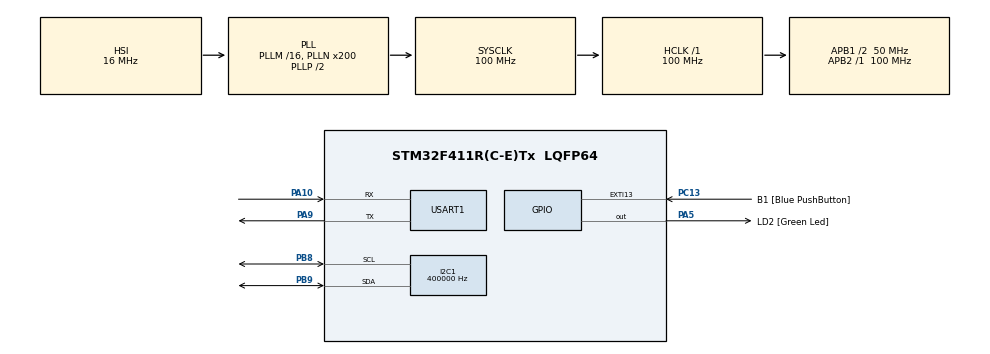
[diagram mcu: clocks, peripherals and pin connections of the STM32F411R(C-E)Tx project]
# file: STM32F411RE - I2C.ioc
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I2C1.ClockSpeed=400000
Mcu.Family=STM32F4
Mcu.Name=STM32F411R(C-E)Tx
Mcu.Package=LQFP64
NVIC.PriorityGroup=NVIC_PRIORITYGROUP_0
NVIC.RTC_Alarm_IRQn=true\:0\:0
NVIC.RTC_WKUP_IRQn=true\:0\:0
PA10.Mode=Asynchronous
PA10.Signal=USART1_RX
PA13.GPIO_Label=TMS
PA13.Mode=Trace-Asynchronous_SW
PA13.Signal=SYS_JTMS-SWDIO
PA14.GPIO_Label=TCK
PA14.Mode=Trace-Asynchronous_SW
PA14.Signal=SYS_JTCK-SWCLK
PA2.GPIO_Label=USART_TX
PA2.GPIO_Mode=GPIO_MODE_AF_PP
PA2.GPIO_PuPd=GPIO_PULLUP
PA2.GPIO_Speed=GPIO_SPEED_LOW
PA2.Signal=USART2_TX
PA3.GPIO_Label=USART_RX
PA3.GPIO_Mode=GPIO_MODE_AF_PP
PA3.GPIO_PuPd=GPIO_PULLUP
PA3.GPIO_Speed=GPIO_SPEED_LOW
PA3.Signal=USART2_RX
PA5.GPIO_Label=LD2 [Green Led]
PA5.GPIO_ModeDefaultOutputPP=GPIO_MODE_OUTPUT_PP
PA5.GPIO_PuPd=GPIO_NOPULL
PA5.GPIO_Speed=GPIO_SPEED_LOW
PA5.Signal=GPIO_Output
PA9.Mode=Asynchronous
PA9.Signal=USART1_TX
PB3.GPIO_Label=SWO
PB3.Mode=Trace-Asynchronous_SW
PB3.Signal=SYS_JTDO-SWO
PB8.GPIO_Mode=GPIO_MODE_AF_OD
PB8.GPIO_PuPd=GPIO_NOPULL
PB8.GPIO_Speed=GPIO_SPEED_MEDIUM
PB8.Mode=I2C
PB8.Signal=I2C1_SCL
PB9.GPIO_Mode=GPIO_MODE_AF_OD
PB9.GPIO_PuPd=GPIO_NOPULL
PB9.GPIO_Speed=GPIO_SPEED_MEDIUM
PB9.Mode=I2C
PB9.Signal=I2C1_SDA
PC13-ANTI_TAMP.GPIO_Label=B1 [Blue PushButton]
PC13-ANTI_TAMP.GPIO_ModeDefaultEXTI=GPIO_MODE_EVT_RISING
PC13-ANTI_TAMP.GPIO_PuPd=GPIO_NOPULL
PC13-ANTI_TAMP.Signal=GPXTI13
PC14-OSC32_IN.Mode=LSE-External-Oscillator
PC14-OSC32_IN.Signal=RCC_OSC32_IN
PC15-OSC32_OUT.Mode=LSE-External-Oscillator
PC15-OSC32_OUT.Signal=RCC_OSC32_OUT
PH0\ -\ OSC_IN.Signal=RCC_OSC_IN
PH1\ -\ OSC_OUT.Signal=RCC_OSC_OUT
ProjectManager.TargetToolchain=EWARM 6.70
RCC.48MHZClocksFreq_Value=50000000
RCC.AHBFreq_Value=100000000
RCC.APB1CLKDivider=RCC_HCLK_DIV2
RCC.APB1Freq_Value=50000000
RCC.APB1TimFreq_Value=100000000
RCC.APB2Freq_Value=100000000
RCC.APB2TimFreq_Value=100000000
RCC.ClockTypePCLK1-ClockTree=RCC_CLOCKTYPE_PCLK1
RCC.ClockTypeSysClk-ClockTree=RCC_CLOCKTYPE_SYSCLK
RCC.CortexFreq_Value=12500000
RCC.EnableExtClockForI2S-ClockTree=false
RCC.EnableHSE-ClockTree=false
RCC.EnableHSERTCDevisor-ClockTree=false
RCC.EnableLSE-ClockTree=true
RCC.EnableLSERTC-ClockTree=true
RCC.ExtClockEnable-ClockTree=false
RCC.FLatency-AdvancedSettings=FLASH_LATENCY_3
RCC.HCLKFreq_Value=100000000
RCC.HSEState-ClockTree=RCC_HSE_OFF
RCC.HSE_VALUE=8000000
RCC.HSIState-ClockTree=RCC_HSI_ON
RCC.HSI_VALUE=16000000
RCC.I2SEnable-ClockTree=false
RCC.IWDGEnable-ClockTree=false
RCC.LSEState-ClockTree=RCC_LSE_ON
RCC.LSE_VALUE=32768
RCC.LSIState-ClockTree=RCC_LSI_OFF
RCC.MCO1OutPutEnable-ClockTree=false
RCC.MCO2OutPutEnable-ClockTree=false
RCC.OscillatorTypeHSI-ClockTree=RCC_OSCILLATORTYPE_HSI
RCC.OscillatorTypeLSE-ClockTree=RCC_OSCILLATORTYPE_LSE
RCC.PLLN=200
RCC.PLLState-ClockTree=RCC_PLL_ON
RCC.PWR_Regulator_Voltage_Scale-AdvancedSettings=PWR_REGULATOR_VOLTAGE_SCALE2
RCC.RCC_PERIPHCLK_RTCVar-ClockTree=RCC_PERIPHCLK_RTC
RCC.RCC_RTC_Clock_Source=RCC_RTCCLKSOURCE_LSE
RCC.RNGEnable-ClockTree=false
RCC.RTCEnable-ClockTree=true
RCC.SDIOEnable-ClockTree=false
RCC.SYSCLKFreq_VALUE=100000000
RCC.SYSCLKSource=RCC_SYSCLKSOURCE_PLLCLK
RCC.USBFSEnable-ClockTree=false
RCC.USBHSEnable-ClockTree=false
RCC.VCOOutputFreq_Value=200000000
RTC.Alarm-Alarm\ A=RTC_ALARM_A
RTC.Alarm_B-Alarm\ B=RTC_ALARM_B
RTC.Format=FORMAT_BIN
RTC.OutPut-Alarm\ A=RTC_OUTPUT_DISABLE
RTC.OutPut-Alarm\ B=RTC_OUTPUT_DISABLE
RTC.OutPut-WakeUp=RTC_OUTPUT_DISABLE
RTC.WakeUpClock-WakeUp=RTC_WAKEUPCLOCK_RTCCLK_DIV2
RTC.WakeUpCounter-WakeUp=196
USART1.HwFlowCtl-Asynchronous=UART_HWCONTROL_NONE
USART1.VirtualMode-Asynchronous=VM_ASYNC
VP_RTC_VS_RTC_Alarm_A_Intern.Mode=Alarm A
VP_RTC_VS_RTC_Alarm_B_Intern.Mode=Alarm B
VP_RTC_VS_RTC_WakeUp_intern.Mode=WakeUp

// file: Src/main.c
/**
  ******************************************************************************
  * File Name          : main.c
  * Date               : 27/04/2015 14:41:06
  * Description        : Main program body
  ******************************************************************************
  *
  * COPYRIGHT(c) 2015 STMicroelectronics
  *
  * Redistribution and use in source and binary forms, with or without modification,
  * are permitted provided that the following conditions are met:
  *   1. Redistributions of source code must retain the above copyright notice,
  *      this list of conditions and the following disclaimer.
  *   2. Redistributions in binary form must reproduce the above copyright notice,
  *      this list of conditions and the following disclaimer in the documentation
  *      and/or other materials provided with the distribution.
  *   3. Neither the name of STMicroelectronics nor the names of its contributors
  *      may be used to endorse or promote products derived from this software
  *      without specific prior written permission.
  *
  * THIS SOFTWARE IS PROVIDED BY THE COPYRIGHT HOLDERS AND CONTRIBUTORS "AS IS"
  * AND ANY EXPRESS OR IMPLIED WARRANTIES, INCLUDING, BUT NOT LIMITED TO, THE
  * IMPLIED WARRANTIES OF MERCHANTABILITY AND FITNESS FOR A PARTICULAR PURPOSE ARE
  * DISCLAIMED. IN NO EVENT SHALL THE COPYRIGHT HOLDER OR CONTRIBUTORS BE LIABLE
  * FOR ANY DIRECT, INDIRECT, INCIDENTAL, SPECIAL, EXEMPLARY, OR CONSEQUENTIAL
  * DAMAGES (INCLUDING, BUT NOT LIMITED TO, PROCUREMENT OF SUBSTITUTE GOODS OR
  * SERVICES; LOSS OF USE, DATA, OR PROFITS; OR BUSINESS INTERRUPTION) HOWEVER
  * CAUSED AND ON ANY THEORY OF LIABILITY, WHETHER IN CONTRACT, STRICT LIABILITY,
  * OR TORT (INCLUDING NEGLIGENCE OR OTHERWISE) ARISING IN ANY WAY OUT OF THE USE
  * OF THIS SOFTWARE, EVEN IF ADVISED OF THE POSSIBILITY OF SUCH DAMAGE.
  *
  ******************************************************************************
  */

#include "stm32f4xx_hal.h"

/* USER CODE BEGIN Includes */
#include "FM24VN10.h"
/* USER CODE END Includes */

I2C_HandleTypeDef hi2c1;

RTC_HandleTypeDef hrtc;

UART_HandleTypeDef huart1;

/* USER CODE BEGIN PV */
#define ARRAY_SIZE 10
uint8_t write_data[ARRAY_SIZE];
uint8_t read_data[ARRAY_SIZE];
/* USER CODE END PV */

void SystemClock_Config(void);
static void MX_GPIO_Init(void);
static void MX_I2C1_Init(void);
static void MX_RTC_Init(void);
static void MX_USART1_UART_Init(void);

int main(void)
{

  /* USER CODE BEGIN 1 */
  uint32_t i;
  /* USER CODE END 1 */

  /* MCU Configuration----------------------------------------------------------*/

  /* Reset of all peripherals, Initializes the Flash interface and the Systick. */
  HAL_Init();

  /* Configure the system clock */
  SystemClock_Config();

  /* Initialize all configured peripherals */
  MX_GPIO_Init();
  MX_I2C1_Init();
  MX_RTC_Init();
  MX_USART1_UART_Init();

  /* USER CODE BEGIN 2 */
  for(i=0; i<ARRAY_SIZE; i++){
    write_data[i] = i;
  }

  // Write some data to the selected address
  FRAM_MultiByte_Write(&hi2c1, 0x10000, &write_data[0], ARRAY_SIZE);

  // Read the data from the selected address
  FRAM_MultiByte_Selective_Read(&hi2c1, 0x10000, &read_data[0], ARRAY_SIZE);

  /* USER CODE END 2 */

  while (1)
  {
  }

}

/** System Clock Configuration
*/
void SystemClock_Config(void)
{

  RCC_OscInitTypeDef RCC_OscInitStruct;
  RCC_ClkInitTypeDef RCC_ClkInitStruct;
  RCC_PeriphCLKInitTypeDef PeriphClkInitStruct;

  __PWR_CLK_ENABLE();

  __HAL_PWR_VOLTAGESCALING_CONFIG(PWR_REGULATOR_VOLTAGE_SCALE2);

  RCC_OscInitStruct.OscillatorType = RCC_OSCILLATORTYPE_HSI|RCC_OSCILLATORTYPE_LSE;
  RCC_OscInitStruct.LSEState = RCC_LSE_ON;
  RCC_OscInitStruct.HSIState = RCC_HSI_ON;
  RCC_OscInitStruct.HSICalibrationValue = 6;
  RCC_OscInitStruct.PLL.PLLState = RCC_PLL_ON;
  RCC_OscInitStruct.PLL.PLLSource = RCC_PLLSOURCE_HSI;
  RCC_OscInitStruct.PLL.PLLM = 16;
  RCC_OscInitStruct.PLL.PLLN = 200;
  RCC_OscInitStruct.PLL.PLLP = RCC_PLLP_DIV2;
  RCC_OscInitStruct.PLL.PLLQ = 4;
  HAL_RCC_OscConfig(&RCC_OscInitStruct);

  RCC_ClkInitStruct.ClockType = RCC_CLOCKTYPE_SYSCLK|RCC_CLOCKTYPE_PCLK1;
  RCC_ClkInitStruct.SYSCLKSource = RCC_SYSCLKSOURCE_PLLCLK;
  RCC_ClkInitStruct.AHBCLKDivider = RCC_SYSCLK_DIV1;
  RCC_ClkInitStruct.APB1CLKDivider = RCC_HCLK_DIV2;
  RCC_ClkInitStruct.APB2CLKDivider = RCC_HCLK_DIV1;
  HAL_RCC_ClockConfig(&RCC_ClkInitStruct, FLASH_LATENCY_3);

  PeriphClkInitStruct.PeriphClockSelection = RCC_PERIPHCLK_RTC;
  PeriphClkInitStruct.RTCClockSelection = RCC_RTCCLKSOURCE_LSE;
  HAL_RCCEx_PeriphCLKConfig(&PeriphClkInitStruct);

}

/* I2C1 init function */
void MX_I2C1_Init(void)
{

  hi2c1.Instance = I2C1;
  hi2c1.Init.ClockSpeed = 400000;
  hi2c1.Init.DutyCycle = I2C_DUTYCYCLE_2;
  hi2c1.Init.OwnAddress1 = 0;
  hi2c1.Init.AddressingMode = I2C_ADDRESSINGMODE_7BIT;
  hi2c1.Init.DualAddressMode = I2C_DUALADDRESS_DISABLED;
  hi2c1.Init.OwnAddress2 = 0;
  hi2c1.Init.GeneralCallMode = I2C_GENERALCALL_DISABLED;
  hi2c1.Init.NoStretchMode = I2C_NOSTRETCH_DISABLED;
  HAL_I2C_Init(&hi2c1);

}

/* RTC init function */
void MX_RTC_Init(void)
{

  RTC_TimeTypeDef sTime;
  RTC_DateTypeDef sDate;
  RTC_AlarmTypeDef sAlarm;

    /**Initialize RTC and set the Time and Date
    */
  hrtc.Instance = RTC;
  hrtc.Init.HourFormat = RTC_HOURFORMAT_24;
  hrtc.Init.AsynchPrediv = 127;
  hrtc.Init.SynchPrediv = 255;
  hrtc.Init.OutPut = RTC_OUTPUT_DISABLE;
  hrtc.Init.OutPutPolarity = RTC_OUTPUT_POLARITY_HIGH;
  hrtc.Init.OutPutType = RTC_OUTPUT_TYPE_OPENDRAIN;
  HAL_RTC_Init(&hrtc);

  sTime.Hours = 0;
  sTime.Minutes = 0;
  sTime.Seconds = 0;
  sTime.SubSeconds = 0;
  sTime.TimeFormat = RTC_HOURFORMAT12_AM;
  sTime.DayLightSaving = RTC_DAYLIGHTSAVING_NONE;
  sTime.StoreOperation = RTC_STOREOPERATION_RESET;
  HAL_RTC_SetTime(&hrtc, &sTime, FORMAT_BIN);

  sDate.WeekDay = RTC_WEEKDAY_MONDAY;
  sDate.Month = RTC_MONTH_JANUARY;
  sDate.Date = 1;
  sDate.Year = 0;
  HAL_RTC_SetDate(&hrtc, &sDate, FORMAT_BIN);

    /**Enable the Alarm A
    */
  sAlarm.AlarmTime.Hours = 0;
  sAlarm.AlarmTime.Minutes = 0;
  sAlarm.AlarmTime.Seconds = 0;
  sAlarm.AlarmTime.SubSeconds = 0;
  sAlarm.AlarmTime.TimeFormat = RTC_HOURFORMAT12_AM;
  sAlarm.AlarmTime.DayLightSaving = RTC_DAYLIGHTSAVING_NONE;
  sAlarm.AlarmTime.StoreOperation = RTC_STOREOPERATION_RESET;
  sAlarm.AlarmMask = RTC_ALARMMASK_NONE;
  sAlarm.AlarmSubSecondMask = RTC_ALARMSUBSECONDMASK_ALL;
  sAlarm.AlarmDateWeekDaySel = RTC_ALARMDATEWEEKDAYSEL_DATE;
  sAlarm.AlarmDateWeekDay = 1;
  sAlarm.Alarm = RTC_ALARM_A;
  HAL_RTC_SetAlarm_IT(&hrtc, &sAlarm, FORMAT_BIN);

    /**Enable the Alarm B
    */
  sAlarm.Alarm = RTC_ALARM_B;
  HAL_RTC_SetAlarm_IT(&hrtc, &sAlarm, FORMAT_BIN);

    /**Enable the WakeUp
    */
  HAL_RTCEx_SetWakeUpTimer_IT(&hrtc, 196, RTC_WAKEUPCLOCK_RTCCLK_DIV2);

}

/* USART1 init function */
void MX_USART1_UART_Init(void)
{

  huart1.Instance = USART1;
  huart1.Init.BaudRate = 115200;
  huart1.Init.WordLength = UART_WORDLENGTH_8B;
  huart1.Init.StopBits = UART_STOPBITS_1;
  huart1.Init.Parity = UART_PARITY_NONE;
  huart1.Init.Mode = UART_MODE_TX_RX;
  huart1.Init.HwFlowCtl = UART_HWCONTROL_NONE;
  huart1.Init.OverSampling = UART_OVERSAMPLING_16;
  HAL_UART_Init(&huart1);

}

/** Configure pins as
        * Analog
        * Input
        * Output
        * EVENT_OUT
        * EXTI
     PA2   ------> USART2_TX
     PA3   ------> USART2_RX
*/
void MX_GPIO_Init(void)
{

  GPIO_InitTypeDef GPIO_InitStruct;

  /* GPIO Ports Clock Enable */
  __GPIOC_CLK_ENABLE();
  __GPIOH_CLK_ENABLE();
  __GPIOA_CLK_ENABLE();
  __GPIOB_CLK_ENABLE();

  /*Configure GPIO pin : PC13 */
  GPIO_InitStruct.Pin = GPIO_PIN_13;
  GPIO_InitStruct.Mode = GPIO_MODE_EVT_RISING;
  GPIO_InitStruct.Pull = GPIO_NOPULL;
  HAL_GPIO_Init(GPIOC, &GPIO_InitStruct);

  /*Configure GPIO pins : PA2 PA3 */
  GPIO_InitStruct.Pin = GPIO_PIN_2|GPIO_PIN_3;
  GPIO_InitStruct.Mode = GPIO_MODE_AF_PP;
  GPIO_InitStruct.Pull = GPIO_PULLUP;
  GPIO_InitStruct.Speed = GPIO_SPEED_LOW;
  GPIO_InitStruct.Alternate = GPIO_AF7_USART2;
  HAL_GPIO_Init(GPIOA, &GPIO_InitStruct);

  /*Configure GPIO pin : PA5 */
  GPIO_InitStruct.Pin = GPIO_PIN_5;
  GPIO_InitStruct.Mode = GPIO_MODE_OUTPUT_PP;
  GPIO_InitStruct.Pull = GPIO_NOPULL;
  GPIO_InitStruct.Speed = GPIO_SPEED_LOW;
  HAL_GPIO_Init(GPIOA, &GPIO_InitStruct);

}

/************************ (C) COPYRIGHT STMicroelectronics *****END OF FILE****/
